# IRQScopeDemoM4 register map
File version: 1.0
Authored synthetic device model for the IRQScope demonstration.
CPU: CM4 r0p1, little endian, no MPU, no FPU, DSP, 3 interrupt priority bits
Registers are 32-bit, read-write, reset 0x0 unless marked. A register's access mark holds for its fields unless they carry their own. Offsets are from the block's base; lines under a group give offsets from that group; [hi:lo] are bit positions; {n}, {i} and the like mark numbered series; 'fields as' and 'values as' point back to an identical list; <NAME> marks a mode.

## Memory map
0x40013000 SIMUART — Synthetic UART-like peripheral used only by the demo fixture.

## SIMUART — Synthetic UART-like peripheral used only by the demo fixture.
Base 0x40013000
0x00 STATUS read-clears — Reading this synthetic status register clears its event state.
  [0] READY ro read-clears — Ready/completion indication.
    on read: 0=NOT_READY; 1=READY
0x04 DATA — Transmit/receive data register.
  [7:0] VALUE
0x08 CONTROL — Transfer control register.
  [0] START
    on write: 0=IDLE; 1=BEGIN_TRANSFER
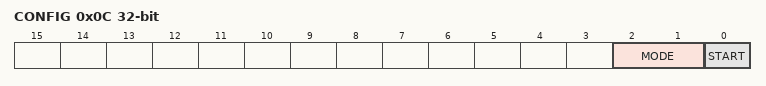
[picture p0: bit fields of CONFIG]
0x0C CONFIG range 0..3 — Ordinary read/write configuration word; writes replace the full modeled word.
  [2:1] MODE
    on write: 0=STANDARD; 1=FAST; 2=DIAGNOSTIC
  [0] START
    on write: 0=IDLE; 1=ENABLED
0x10 EVENTS write-1-clears — Write-one-to-clear event flags used to demonstrate disjoint acknowledgements.
